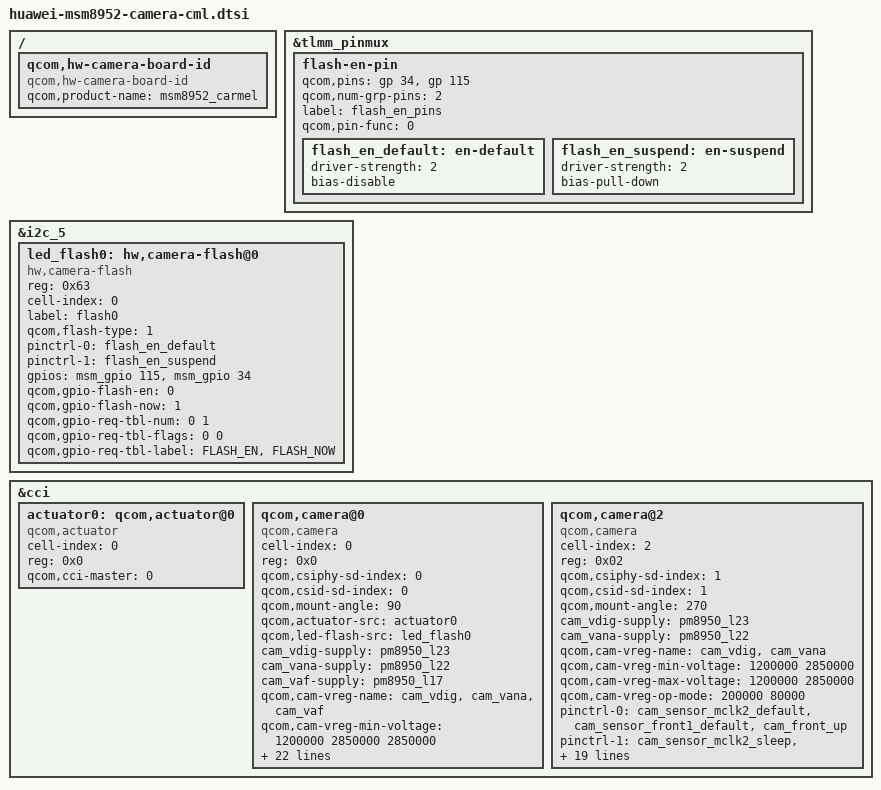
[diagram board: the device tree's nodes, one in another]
/*
 * Copyright (c) 2015, The Linux Foundation. All rights reserved.
 *
 * This program is free software; you can redistribute it and/or modify
 * it under the terms of the GNU General Public License version 2 and
 * only version 2 as published by the Free Software Foundation.
 *
 * This program is distributed in the hope that it will be useful,
 * but WITHOUT ANY WARRANTY; without even the implied warranty of
 * MERCHANTABILITY or FITNESS FOR A PARTICULAR PURPOSE.  See the
 * GNU General Public License for more details.
 */

/ {
    qcom,hw-camera-board-id {
                compatible = "qcom,hw-camera-board-id";
                qcom,product-name = "msm8952_carmel";
        };
};

 &tlmm_pinmux {
	flash-en-pin {
		qcom,pins = <&gp 34>, <&gp 115>;
		qcom,num-grp-pins = <2>;
		label = "flash_en_pins";
		qcom,pin-func = <0>;

		flash_en_default: en-default {
			driver-strength = <2>;
			bias-disable;
		};
		flash_en_suspend: en-suspend {
			driver-strength = <2>;
			bias-pull-down;
		};
	};
};

&i2c_5 { /* BLSP1 QUP2 */
	led_flash0:hw,camera-flash@0 {
		reg = <0x63>;
		cell-index = <0>;
		compatible = "hw,camera-flash";
		label = "flash0";
		qcom,flash-type = <1>;
		pinctrl-names = "cam_flash_default","cam_flash_suspend";
		pinctrl-0 = <&flash_en_default>;
		pinctrl-1 = <&flash_en_suspend>;
		gpios = <&msm_gpio 115 0>,
			<&msm_gpio 34 0>;
		qcom,gpio-flash-en = <0>;
		qcom,gpio-flash-now = <1>;
		qcom,gpio-req-tbl-num = <0 1>;
		qcom,gpio-req-tbl-flags = <0 0>;
		qcom,gpio-req-tbl-label = "FLASH_EN",
			"FLASH_NOW";
	};
};

&cci {
	actuator0: qcom,actuator@0 {
		cell-index = <0>;
		reg = <0x0>;
		compatible = "qcom,actuator";
		qcom,cci-master = <0>;
	};
	qcom,camera@0 {
		cell-index = <0>;
		compatible = "qcom,camera";
		reg = <0x0>;
		qcom,csiphy-sd-index = <0>;
		qcom,csid-sd-index = <0>;
		qcom,mount-angle = <90>;
		qcom,actuator-src = <&actuator0>;
		qcom,led-flash-src = <&led_flash0>;

		cam_vdig-supply = <&pm8950_l23>;
		cam_vana-supply = <&pm8950_l22>;
		cam_vaf-supply = <&pm8950_l17>;
		qcom,cam-vreg-name = "cam_vdig", "cam_vana", "cam_vaf";
		qcom,cam-vreg-min-voltage = <1200000 2850000 2850000>;
		qcom,cam-vreg-max-voltage = <1200000 2850000 2850000>;
		qcom,cam-vreg-op-mode = <200000 80000 100000>;
		pinctrl-names = "cam_default", "cam_suspend";
		pinctrl-0 = <&cam_sensor_mclk0_default
				&cam_sensor_rear_default>;
		pinctrl-1 = <&cam_sensor_mclk0_sleep &cam_sensor_rear_sleep>;
		gpios = <&msm_gpio 26 0>,
			<&msm_gpio 133 0>,
			<&msm_gpio 36 0>,
			<&msm_gpio 35 0>,
			<&msm_gpio 131 0>;
		qcom,gpio-vio = <1>;	
		qcom,gpio-reset = <2>;
		qcom,gpio-af-pwdm = <3>;
		qcom,gpio-cam-id = <4>;
		qcom,gpio-req-tbl-num = <0 1 2 3 4>;
		qcom,gpio-req-tbl-flags = <1 0 0 0 1>;
		qcom,gpio-req-tbl-label = "CAMIF_MCLK0",
			"CAM_VIO_EN",
			"CAM_RESET0",
			"CAM_AF_PWD0",
			"CAM_ID0";
		qcom,sensor-position = <0>;
		qcom,sensor-mode = <0>;
		qcom,cci-master = <0>;
		status = "ok";
		clocks = <&clock_gcc clk_mclk0_clk_src>,
				<&clock_gcc clk_gcc_camss_mclk0_clk>;
		clock-names = "cam_src_clk", "cam_clk";
	};

	qcom,camera@2 {
		cell-index = <2>;
		compatible = "qcom,camera";
		reg = <0x02>;
		qcom,csiphy-sd-index = <1>;
		qcom,csid-sd-index = <1>;
		qcom,mount-angle = <270>;
		cam_vdig-supply = <&pm8950_l23>;
		cam_vana-supply = <&pm8950_l22>;
		qcom,cam-vreg-name = "cam_vdig", "cam_vana";
		qcom,cam-vreg-min-voltage = <1200000 2850000>;
		qcom,cam-vreg-max-voltage = <1200000 2850000>;
		qcom,cam-vreg-op-mode = <200000 80000>;
		pinctrl-names = "cam_default", "cam_suspend", "cam_up","cam_down";
		pinctrl-0 = <&cam_sensor_mclk2_default &cam_sensor_front1_default &cam_front_up>;
		pinctrl-1 = <&cam_sensor_mclk2_sleep &cam_sensor_front1_sleep &cam_front_up>;
		pinctrl-2 = <&cam_sensor_mclk2_default &cam_sensor_front1_default &cam_front_up>;
		pinctrl-3 = <&cam_sensor_mclk2_default &cam_sensor_front1_default &cam_front_down>;
		gpios = <&msm_gpio 28 0>,
			<&msm_gpio 133 0>,
			<&msm_gpio 40 0>,
			<&msm_gpio 39 0>;
		qcom,gpio-vio = <1>;
		qcom,gpio-reset = <2>;
		qcom,gpio-cam-id = <3>;
		qcom,gpio-req-tbl-num = <0 1 2 3>;
		qcom,gpio-req-tbl-flags = <1 0 0 1>;
		qcom,gpio-req-tbl-label = "CAMIF_MCLK2",
			"CAM_VIO_EN2",		
			"CAM_RESET2",
			"CAM_ID2";
		qcom,sensor-position = <1>;
		qcom,sensor-mode = <0>;
		qcom,cci-master = <1>;
		clocks = <&clock_gcc clk_mclk2_clk_src>,
			<&clock_gcc clk_gcc_camss_mclk2_clk>;
		clock-names = "cam_src_clk", "cam_clk";
		status = "ok";
	};
};
